# RZ/A1H register map
Vendor: Renesas
Registers are 32-bit, read-write, reset 0x0 unless marked. A register's access mark holds for its fields unless they carry their own. Offsets are from the block's base; [hi:lo] are bit positions; {n}, {i} and the like mark numbered series.

## CPG
Base 0xFCFE0010
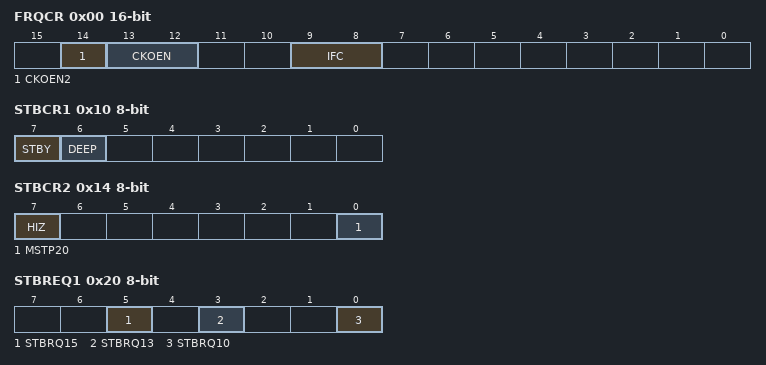
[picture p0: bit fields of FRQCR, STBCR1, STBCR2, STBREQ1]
0x00 FRQCR 16-bit
  [14] CKOEN2
    0=UNSTABLE_CLOCK_OUT (Unstable clock output); 1=LOW_OUT (Low-level output)
  [13:12] CKOEN
    0=OUT_HIZ_HIZ (Normal operation: output, Software Standy Mode: Hi-Z, Deep Standby Mode: Hi-Z); 1=OUT_LOW_LOW (Normal operation: output, Software Standy Mode: low-level output, Deep Standby Mode: low-level output); 2=OUT_OUT_OUT (Normal operation: output, Software Standy Mode: unstable clock output, Deep Standby Mode: low-level for high-level output); 3=HIZ_HIZ_HIZ (Normal operation: Hi-Z, Software Standy Mode: Hi-Z, Deep Standby Mode: Hi-Z)
  [9:8] IFC
    0=UNITY (1/1 time); 1=TWO_THIRD (2/3 time); 3=ONE_THIRD (1/3 time)
0x04 FRQCR2 16-bit
  [1:0] GFC
    1=TWO_THIRD (2/3 time); 3=ONE_THIRD (1/3 time)
0x08 CPUSTS 8-bit
  [4] ISBUSY0
0x10 STBCR1 8-bit
  [7] STBY, [6] DEEP
0x14 STBCR2 8-bit
  [7] HIZ, [0] MSTP20
0x20 STBREQ1 8-bit
  [5] STBRQ15, [3] STBRQ13, [0] STBRQ10
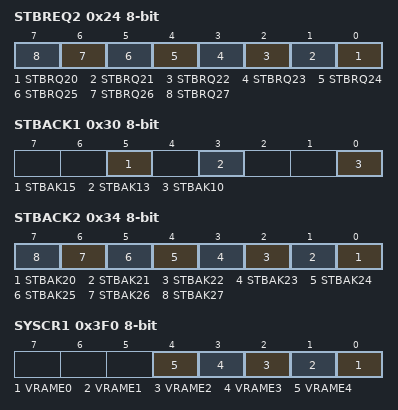
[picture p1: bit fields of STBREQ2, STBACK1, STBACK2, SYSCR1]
0x24 STBREQ2 8-bit
  [n-20] STBRQ{n} (n=20..27)
0x30 STBACK1 8-bit
  [5] STBAK15, [3] STBAK13, [0] STBAK10
0x34 STBACK2 8-bit
  [n-20] STBAK{n} (n=20..27)
0x3F0 SYSCR1 8-bit
  [n] VRAME{n} (n=0..4)
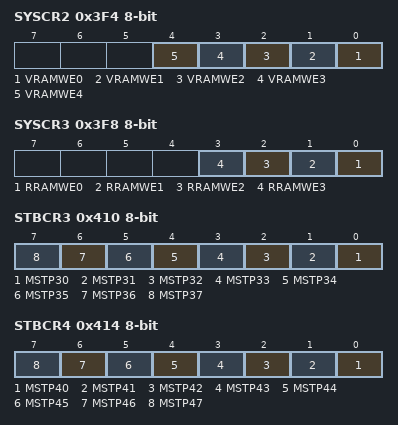
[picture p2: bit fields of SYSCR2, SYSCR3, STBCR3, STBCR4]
0x3F4 SYSCR2 8-bit
  [n] VRAMWE{n} (n=0..4)
0x3F8 SYSCR3 8-bit
  [n] RRAMWE{n} (n=0..3)
0x410 STBCR3 8-bit
  [n-30] MSTP{n} (n=30..37)
0x414 STBCR4 8-bit
  [n-40] MSTP{n} (n=40..47)
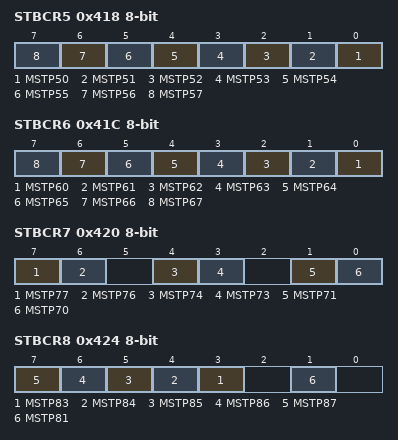
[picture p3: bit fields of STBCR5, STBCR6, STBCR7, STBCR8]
0x418 STBCR5 8-bit
  [n-50] MSTP{n} (n=50..57)
0x41C STBCR6 8-bit
  [n-60] MSTP{n} (n=60..67)
0x420 STBCR7 8-bit
  [7] MSTP77, [6] MSTP76, [4] MSTP74, [3] MSTP73, [1] MSTP71, [0] MSTP70
0x424 STBCR8 8-bit
  [n-80] MSTP{n} (n=83..87), [1] MSTP81
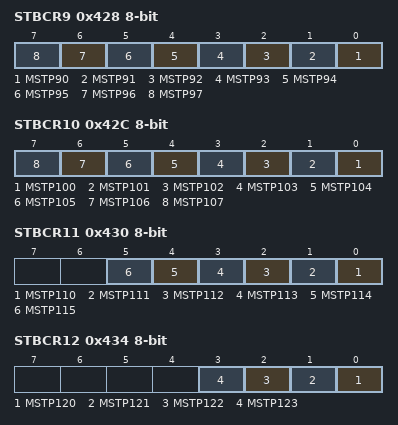
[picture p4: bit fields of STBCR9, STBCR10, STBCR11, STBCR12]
0x428 STBCR9 8-bit
  [n-90] MSTP{n} (n=90..97)
0x42C STBCR10 8-bit
  [n-100] MSTP{n} (n=100..107)
0x430 STBCR11 8-bit
  [n-110] MSTP{n} (n=110..115)
0x434 STBCR12 8-bit
  [n-120] MSTP{n} (n=120..123)
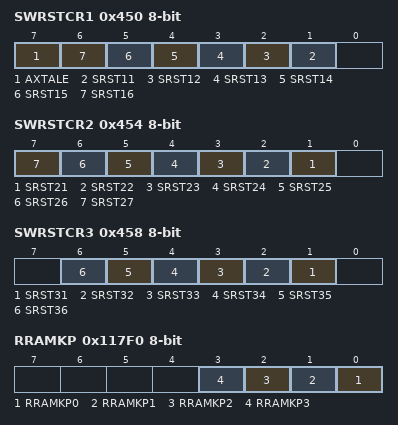
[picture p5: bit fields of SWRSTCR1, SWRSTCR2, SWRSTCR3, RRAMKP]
0x450 SWRSTCR1 8-bit
  [7] AXTALE, [n-10] SRST{n} (n=11..16)
0x454 SWRSTCR2 8-bit
  [n-20] SRST{n} (n=21..27)
0x458 SWRSTCR3 8-bit
  [n-30] SRST{n} (n=31..36)
0x460 STBCR13 8-bit
0x117F0 RRAMKP 8-bit
  [n] RRAMKP{n} (n=0..3)
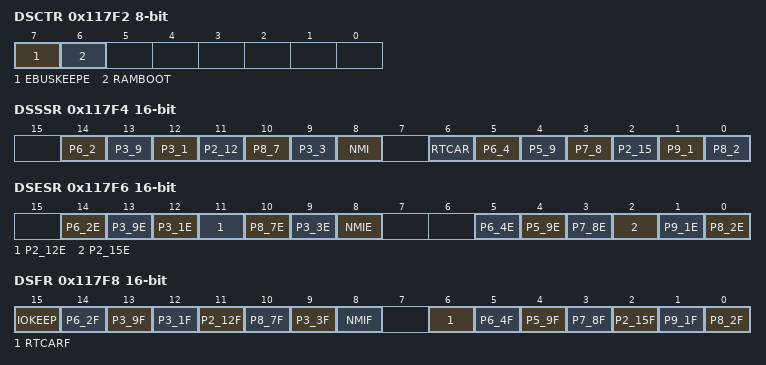
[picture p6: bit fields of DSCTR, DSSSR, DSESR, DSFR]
0x117F2 DSCTR 8-bit
  [7] EBUSKEEPE, [6] RAMBOOT
0x117F4 DSSSR 16-bit
  [14] P6_2, [13] P3_9, [12] P3_1, [11] P2_12, [10] P8_7, [9] P3_3, [8] NMI, [6] RTCAR, [5] P6_4, [4] P5_9, [3] P7_8, [2] P2_15, [1] P9_1, [0] P8_2
0x117F6 DSESR 16-bit
  [14] P6_2E, [13] P3_9E, [12] P3_1E, [11] P2_12E, [10] P8_7E, [9] P3_3E, [8] NMIE, [5] P6_4E, [4] P5_9E, [3] P7_8E, [2] P2_15E, [1] P9_1E, [0] P8_2E
0x117F8 DSFR 16-bit
  [15] IOKEEP, [14] P6_2F, [13] P3_9F, [12] P3_1F, [11] P2_12F, [10] P8_7F, [9] P3_3F, [8] NMIF, [6] RTCARF, [5] P6_4F, [4] P5_9F, [3] P7_8F, [2] P2_15F, [1] P9_1F, [0] P8_2F
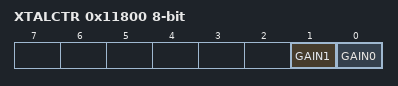
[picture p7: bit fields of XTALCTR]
0x11800 XTALCTR 8-bit
  [1] GAIN1, [0] GAIN0

## DISC0
Base 0xFCFFA800
Same registers: DISC1 0xFCFFB000
0x00 DOCMCR
0x04 DOCMSTR
0x08 DOCMCLSTR
0x0C DOCMIENR
0x14 DOCMPMR
0x18 DOCMECRCR
0x1C DOCMCCRCR
0x20 DOCMSPXR
0x24 DOCMSPYR
0x28 DOCMSZXR
0x2C DOCMSZYR
0x30 DOCMCRCIR

## DMAC
Base 0xE8200000
{0x0+0x40*i} N0SA_{i} (i=0..7)
{0x4+0x40*i} N0DA_{i} (i=0..7)
{0x8+0x40*i} N0TB_{i} (i=0..7)
{0xC+0x40*i} N1SA_{i} (i=0..7)
{0x10+0x40*i} N1DA_{i} (i=0..7)
{0x14+0x40*i} N1TB_{i} (i=0..7)
{0x18+0x40*i} CRSA_{i} (i=0..7)
{0x1C+0x40*i} CRDA_{i} (i=0..7)
{0x20+0x40*i} CRTB_{i} (i=0..7)
{0x24+0x40*i} CHSTAT_{i} (i=0..7)
{0x28+0x40*i} CHCTRL_{i} (i=0..7)
{0x2C+0x40*i} CHCFG_{i} (i=0..7)
{0x30+0x40*i} CHITVL_{i} (i=0..7)
{0x34+0x40*i} CHEXT_{i} (i=0..7)
{0x38+0x40*i} NXLA_{i} (i=0..7)
{0x3C+0x40*i} CRLA_{i} (i=0..7)
0x300 DCTRL_0_7
0x310 DSTAT_EN_0_7
0x314 DSTAT_ER_0_7
0x318 DSTAT_END_0_7
0x31C DSTAT_TC_0_7
0x320 DSTAT_SUS_0_7
{0x200+0x40*i} N0SA_{i} (i=8..15)
{0x204+0x40*i} N0DA_{i} (i=8..15)
{0x208+0x40*i} N0TB_{i} (i=8..15)
{0x20C+0x40*i} N1SA_{i} (i=8..15)
{0x210+0x40*i} N1DA_{i} (i=8..15)
{0x214+0x40*i} N1TB_{i} (i=8..15)
{0x218+0x40*i} CRSA_{i} (i=8..15)
{0x21C+0x40*i} CRDA_{i} (i=8..15)
{0x220+0x40*i} CRTB_{i} (i=8..15)
{0x224+0x40*i} CHSTAT_{i} (i=8..15)
{0x228+0x40*i} CHCTRL_{i} (i=8..15)
{0x22C+0x40*i} CHCFG_{i} (i=8..15)
{0x230+0x40*i} CHITVL_{i} (i=8..15)
{0x234+0x40*i} CHEXT_{i} (i=8..15)
{0x238+0x40*i} NXLA_{i} (i=8..15)
{0x23C+0x40*i} CRLA_{i} (i=8..15)
0x700 DCTRL_8_15
0x710 DSTAT_EN_8_15
0x714 DSTAT_ER_8_15
0x718 DSTAT_END_8_15
0x71C DSTAT_TC_8_15
0x720 DSTAT_SUS_8_15
{0x14DE1000+4i} DMARS{i} (i=0..7)
